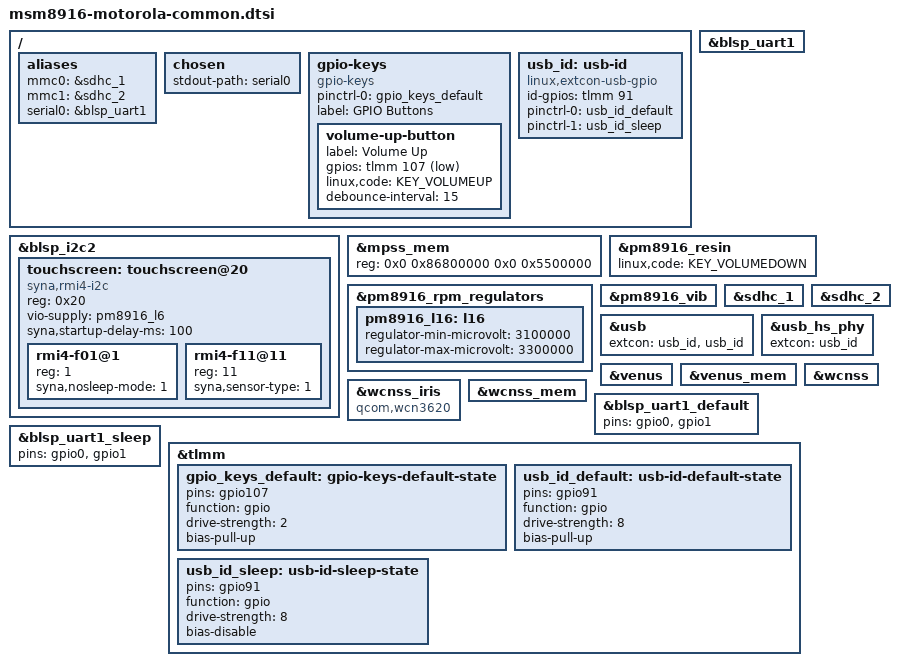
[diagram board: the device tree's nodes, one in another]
// SPDX-License-Identifier: GPL-2.0-only

#include "msm8916-pm8916.dtsi"
#include "msm8916-modem-qdsp6.dtsi"

#include <dt-bindings/gpio/gpio.h>
#include <dt-bindings/input/input.h>
#include <dt-bindings/interrupt-controller/irq.h>

/ {
	aliases {
		mmc0 = &sdhc_1; /* eMMC */
		mmc1 = &sdhc_2; /* SD card */
		serial0 = &blsp_uart1;
	};

	chosen {
		stdout-path = "serial0";
	};

	gpio-keys {
		compatible = "gpio-keys";

		pinctrl-0 = <&gpio_keys_default>;
		pinctrl-names = "default";

		label = "GPIO Buttons";

		volume-up-button {
			label = "Volume Up";
			gpios = <&tlmm 107 GPIO_ACTIVE_LOW>;
			linux,code = <KEY_VOLUMEUP>;
			debounce-interval = <15>;
		};
	};

	usb_id: usb-id {
		compatible = "linux,extcon-usb-gpio";
		id-gpios = <&tlmm 91 GPIO_ACTIVE_HIGH>;
		pinctrl-0 = <&usb_id_default>;
		pinctrl-1 = <&usb_id_sleep>;
		pinctrl-names = "default", "sleep";
	};
};

&blsp_i2c2 {
	status = "okay";

	touchscreen: touchscreen@20 {
		compatible = "syna,rmi4-i2c";
		reg = <0x20>;
		#address-cells = <1>;
		#size-cells = <0>;

		vio-supply = <&pm8916_l6>;

		syna,startup-delay-ms = <100>;

		rmi4-f01@1 {
			reg = <1>;
			syna,nosleep-mode = <1>; /* Allow sleeping */
		};

		rmi4-f11@11 {
			reg = <11>;
			syna,sensor-type = <1>; /* Touchscreen */
		};
	};
};

&blsp_uart1 {
	status = "okay";
};

&mpss_mem {
	reg = <0x0 0x86800000 0x0 0x5500000>;
};

&pm8916_resin {
	linux,code = <KEY_VOLUMEDOWN>;
	status = "okay";
};

&pm8916_rpm_regulators {
	pm8916_l16: l16 {
		regulator-min-microvolt = <3100000>;
		regulator-max-microvolt = <3300000>;
	};
};

&pm8916_vib {
	status = "okay";
};

&sdhc_1 {
	status = "okay";
};

&sdhc_2 {
	status = "okay";
};

&usb {
	extcon = <&usb_id>, <&usb_id>;
	status = "okay";
};

&usb_hs_phy {
	extcon = <&usb_id>;
};

&venus {
	status = "okay";
};

&venus_mem {
	status = "okay";
};

&wcnss {
	status = "okay";
};

&wcnss_iris {
	compatible = "qcom,wcn3620";
};

&wcnss_mem {
	status = "okay";
};

/* CTS/RTX are not used */
&blsp_uart1_default {
	pins = "gpio0", "gpio1";
};
&blsp_uart1_sleep {
	pins = "gpio0", "gpio1";
};

&tlmm {
	gpio_keys_default: gpio-keys-default-state {
		pins = "gpio107";
		function = "gpio";
		drive-strength = <2>;
		bias-pull-up;
	};

	usb_id_default: usb-id-default-state {
		pins = "gpio91";
		function = "gpio";
		drive-strength = <8>;
		bias-pull-up;
	};

	usb_id_sleep: usb-id-sleep-state {
		pins = "gpio91";
		function = "gpio";
		drive-strength = <8>;
		bias-disable;
	};
};
